# HDSC_HC32F165 register map
Vendor: HDSC; Series: ARMCM0P; File version: 1.0
CPU: CM0P r0p1, little endian, MPU, FPU, 4 interrupt priority bits
Registers are 32-bit, read-write, reset 0x0 unless marked. A register's access mark holds for its fields unless they carry their own. Offsets are from the block's base; lines under a group give offsets from that group; [hi:lo] are bit positions; {n}, {i} and the like mark numbered series; 'fields as' and 'values as' point back to an identical list; <NAME> marks a mode.

## Memory map
0x000000C0 ICG size 0x2C
0x40010000 BUZ size 0x5
0x40010400 EFM size 0x289
0x40010800 AOS size 0xB4
0x40010C00 LED size 0x38
0x40017000 TMR4 size 0xE2
0x40017C00 EMB0 size 0x40 — desc EMB
0x40017C20 EMB1 size 0x40 — desc EMB
0x4001BC00 TK size 0x98
0x4001C000 SPI1 size 0x1C — desc SPI
0x4001C400 SPI2 size 0x1C — desc SPI
0x4001D000 USART1 size 0x1C — desc USART
0x4001D400 USART2 size 0x1C — desc USART
0x40021000 USART3 size 0x1C — desc USART
0x40021400 USART4 size 0x1C — desc USART
0x40021800 USART5 size 0x1C — desc USART
0x40021C00 USART6 size 0x1C — desc USART
0x40024000 TMR01 size 0x18 — desc TMR0
0x40024400 TMR02 size 0x18 — desc TMR0
0x40025000 TMRB1 size 0x148 — desc TMRB
0x40025400 TMRB2 size 0x148 — desc TMRB
0x40025800 TMRB3 size 0x148 — desc TMRB
0x40025C00 TMRB4 size 0x148 — desc TMRB
0x40030000 ADC size 0xB2
0x40040000 CTC size 0x10
0x40040400 TMRB5 size 0x148 — desc TMRB
0x40040800 TMRB6 size 0x148 — desc TMRB
0x40048400 FCM size 0x24
0x40049400 SWDT size 0xC
0x4004A000 CMP1 size 0x6 — desc CMP
0x4004A000 CMPCR size 0x103
0x4004A010 CMP2 size 0x6 — desc CMP
0x4004C000 RTC size 0x3D
0x4004E000 I2C1 size 0x34 — desc I2C
0x4004E400 I2C2 size 0x34 — desc I2C
0x40050400 CRC size 0x100
0x40051000 INTC size 0x100
0x40052000 DCU size 0x1C
0x40053000 DMA size 0x210
0x40053800 GPIO size 0x50A
0x40054000 PWC size 0x102
0x40054100 RMU size 0x2
0x40054400 CMU size 0x49
0x40054800 MAU size 0x1C
0xE0042000 DBGC size 0x1C

## ADC
Base 0x40030000
0x00 STR 8-bit
  [0] STRT
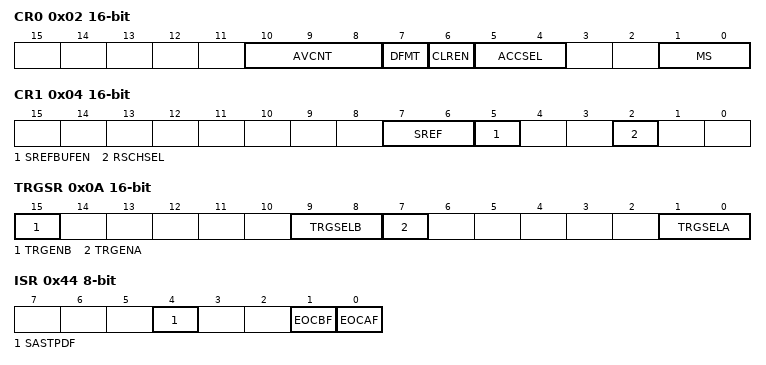
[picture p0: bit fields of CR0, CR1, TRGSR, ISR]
0x02 CR0 16-bit
  [10:8] AVCNT, [7] DFMT, [6] CLREN, [5:4] ACCSEL, [1:0] MS
0x04 CR1 16-bit
  [7:6] SREF, [5] SREFBUFEN, [2] RSCHSEL
0x0A TRGSR 16-bit
  [15] TRGENB, [9:8] TRGSELB, [7] TRGENA, [1:0] TRGSELA
{0x20+i} SSTR{i} 8-bit reset 0x4 (i=0..9)
{0x26+i} SSTR{i} 8-bit reset 0x4 (i=10..17)
0x44 ISR 8-bit ro
  [4] SASTPDF, [1] EOCBF, [0] EOCAF
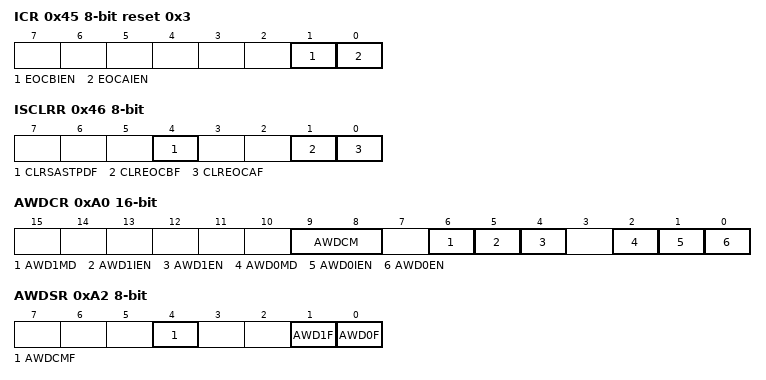
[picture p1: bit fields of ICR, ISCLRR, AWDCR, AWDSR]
0x45 ICR 8-bit reset 0x3
  [1] EOCBIEN, [0] EOCAIEN
0x46 ISCLRR 8-bit wo
  [4] CLRSASTPDF, [1] CLREOCBF, [0] CLREOCAF
{0x50+2i} DR{i} 16-bit ro (i=0..4)
{0x56+2i} DR{i} 16-bit ro (i=5..9)
{0x5C+2i} DR{i} 16-bit ro (i=10..14)
{0x62+2i} DR{i} 16-bit ro (i=15..17)
0xA0 AWDCR 16-bit
  [9:8] AWDCM, [6] AWD1MD, [5] AWD1IEN, [4] AWD1EN, [2] AWD0MD, [1] AWD0IEN, [0] AWD0EN
0xA2 AWDSR 8-bit ro
  [4] AWDCMF, [1] AWD1F, [0] AWD0F
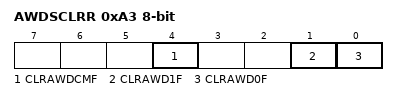
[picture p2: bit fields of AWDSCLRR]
0xA3 AWDSCLRR 8-bit
  [4] CLRAWDCMF, [1] CLRAWD1F, [0] CLRAWD0F
0xA4 AWD0DR0 16-bit
0xA6 AWD0DR1 16-bit reset 0xFFFF
0xA8 AWD0CHSR 16-bit
  [4:0] AWDCH
0xAC AWD1DR0 16-bit
0xAE AWD1DR1 16-bit reset 0xFFFF
0xB0 AWD1CHSR 16-bit
  [4:0] AWDCH

## AOS
Base 0x40010800
0x00 SWTRG wo
  [0] STRG
0x20 TMR0_HTSSR reset 0xFF
  [7:0] TRGSEL
0x50 TMRB_HTSSR reset 0xFF
  [7:0] TRGSEL
0x60 ADC_ITRGSELR0 reset 0xFF
  [7:0] TRGSEL
0x64 ADC_ITRGSELR1 reset 0xFF
  [7:0] TRGSEL
{0x80+4i} DMA_TRGSEL{i} reset 0xFF (i=0..7)
  [7:0] TRGSEL
0xA0 DCU_TRGSEL reset 0xFF
  [7:0] TRGSEL
0xB0 TMR4_HTSSR reset 0xFF
  [7:0] TRGSEL

## BUZ
Base 0x40010000
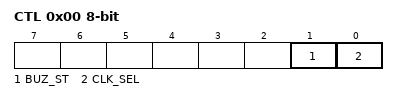
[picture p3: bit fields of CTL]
0x00 CTL 8-bit
  [1] BUZ_ST, [0] CLK_SEL
0x04 CNT 8-bit

## CMP1 — desc CMP
Base 0x4004A000
Same registers: CMP2 0x4004A010
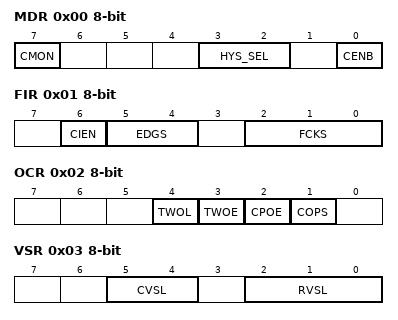
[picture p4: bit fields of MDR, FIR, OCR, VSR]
0x00 MDR 8-bit
  [7] CMON ro, [3:2] HYS_SEL, [0] CENB
0x01 FIR 8-bit
  [6] CIEN, [5:4] EDGS, [2:0] FCKS
0x02 OCR 8-bit
  [4] TWOL, [3] TWOE, [2] CPOE, [1] COPS
0x03 VSR 8-bit
  [5:4] CVSL, [2:0] RVSL
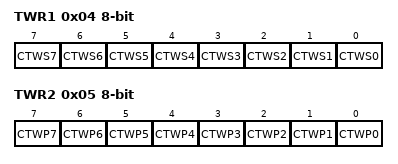
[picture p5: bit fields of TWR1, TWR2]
0x04 TWR1 8-bit
  [n] CTWS{n} (n=0..7)
0x05 TWR2 8-bit
  [n] CTWP{n} (n=0..7)

## CMPCR
Base 0x4004A000; alternate view of CMP1
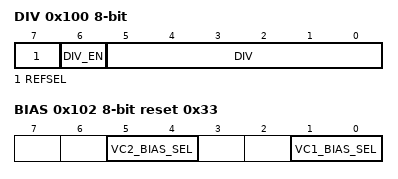
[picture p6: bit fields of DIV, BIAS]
0x100 DIV 8-bit
  [7] REFSEL, [6] DIV_EN, [5:0] DIV
0x102 BIAS 8-bit reset 0x33
  [5:4] VC2_BIAS_SEL, [1:0] VC1_BIAS_SEL
